# S32K322_M7 register map
Vendor: NXP Semiconductors; File version: 1.0
CPU: CM7 r0p1, little endian, MPU, FPU, VTOR, 4 interrupt priority bits
Registers are 32-bit, read-write, reset 0x0 unless marked. A register's access mark holds for its fields unless they carry their own. Offsets are from the block's base; [hi:lo] are bit positions; lines under a group give offsets from that group; {n}, {i} and the like mark numbered series.

## PRAMC_0 — PRAMC
Base 0x40264000
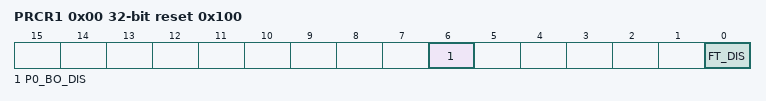
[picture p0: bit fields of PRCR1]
0x00 PRCR1 reset 0x100 — Platform RAM Configuration register 1
  [6] P0_BO_DIS — Port p0 read burst optimization disable.
    0=OPT_YES (64-bit WRP4 read bursts are optimized such that the controller returns a 2-1-1-1 response when PRCR1[FT_DIS ]=1); 1=OPT_NO (64-bit WRP4 read bursts are not optimized; the controller returns a 2-2-2-2 response when PRCR1[FT_DIS ]=1)
  [0] FT_DIS — Flow-through disabled
    0=DIRECT (RAM read data is passed directly to the system bus, incurring no additional latency); 1=REGISTER (RAM read data is registered prior to returning on the system bus, incurring one extra cycle of latency)

## SWT_0 — SWT
Base 0x40270000
Same registers: SWT_1 0x4046C000
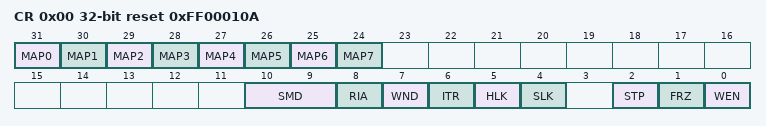
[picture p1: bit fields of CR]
0x00 CR reset 0xFF00010A — Control
  [31-n] MAP{n} (n=0..7) — Master Access Protection {n}
    0=disabled (Access disabled); 1=enabled (Access enabled)
  [10:9] SMD — Service Mode
    0=Fixed Service Sequence; 1=Keyed Service Sequence
  [8] RIA — Reset on Invalid Access
    0=bus_error (Generate a bus error); 1=reset_req (Generate a bus error and reset request)
  [7] WND — Window Mode
    0=Regular mode; 1=windowed (Window mode)
  [6] ITR — Interrupt Then Reset Request
    0=reset_req (Generate a reset request on a timeout); 1=interrupt (Generate an interrupt on an initial timeout; generate a reset request on a second consecutive timeout)
  [5] HLK — Hard Lock
    0=rw (CR, TO, WN, and SK are read/write registers if SLK is also 0); 1=ro (CR, TO, WN, and SK are read-only registers)
  [4] SLK — Soft Lock
    0=rw (CR, TO, WN, and SK are read/write registers if HLK is also 0); 1=ro (CR, TO, WN, and SK are read-only registers)
  [2] STP — Stop Mode Control
    0=continues (Timer continues); 1=stopped (Timer stops)
  [1] FRZ — Debug Mode Control
    0=continues (Timer continues); 1=stopped (Timer stops)
  [0] WEN — Watchdog Enable
    0=disabled; 1=enabled
0x04 IR write-1-clears — Interrupt
  [0] TIF write-1-clears — Timeout Interrupt Flag
    0=no_irq (No interrupt request); 1=irq (Interrupt request due to an initial timeout)
0x08 TO reset 0x320 — Timeout
  [31:0] WTO — Watchdog Timeout
0x0C WN — Window
  [31:0] WST — Window Start Value
0x10 SR — Service
  [15:0] WSC — Watchdog Service Code
0x14 CO ro — Counter Output
  [31:0] CNT — Watchdog Count
0x18 SK — Service Key
  [15:0] SK
0x1C RRR write-1-clears — Event Request
  [0] RRF write-1-clears — Reset Request Flag
    0=no (No reset request); 1=any (Any reset request initiated)

## STM_0 — STM
Base 0x40274000
Same registers: STM_1 0x40474000
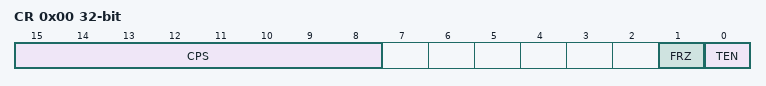
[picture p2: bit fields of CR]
0x00 CR — Control
  [15:8] CPS — Counter Prescaler
  [1] FRZ — Freeze
    0=runs (Timer runs in Debug mode); 1=stop (Timer stops in Debug mode)
  [0] TEN — Timer Enable
    0=disabled; 1=enabled
0x04 CNT — Count
  [31:0] CNT — Timer Count
{0x10+0x10*i} CHANNEL[{i}] (i=0..3) group
  0x00 CCR — Channel Control
    [0] CEN — Channel Enable
      0=disabled; 1=enabled
  0x04 CIR write-1-clears — Channel Interrupt
    [0] CIF write-1-clears — Channel Interrupt Flag
      0=no_irq (Read: IRQ is not asserted. Write: No effect.); 1=irq (Read: IRQ is asserted. Write: Clear the flag.)
  0x08 CMP — Channel Compare

## INTM
Base 0x4027C000
0x00 INTM_MM — Monitor Mode
  [0] MM
    0=disabled; 1=enabled
0x04 INTM_IACK wo — Interrupt Acknowledge
  [9:0] IRQ — This field is used to specify the interrupt request number to stop INTM_TIMERa.
{0x8+0x10*i} mon[{i}] (i=0..3) group
  0x00 INTM_IRQSEL — Interrupt Request Select mon_index
    [9:0] IRQ — This field helps you select the interrupt request number to monitor.
  0x04 INTM_LATENCY — INTM_LATENCYmon_index
    [23:0] LAT — This field helps you select the maximum number of INTM clock cycles allowed for the monitored interrupt request
  0x08 INTM_TIMER — Timer mon_index
    [23:0] TIMER — This field is used to count the number of INTM clock cycles up to 24 bits of resolution.
  0x0C INTM_STATUS ro — Status mon_index
    [0] STATUS — Monitor status
      0=ST02 (INTM_TIMER value has not exceeded the INTM_LATENCY value.); 1=ST01 (INTM_TIMER value has exceeded the INTM_LATENCY value.)
